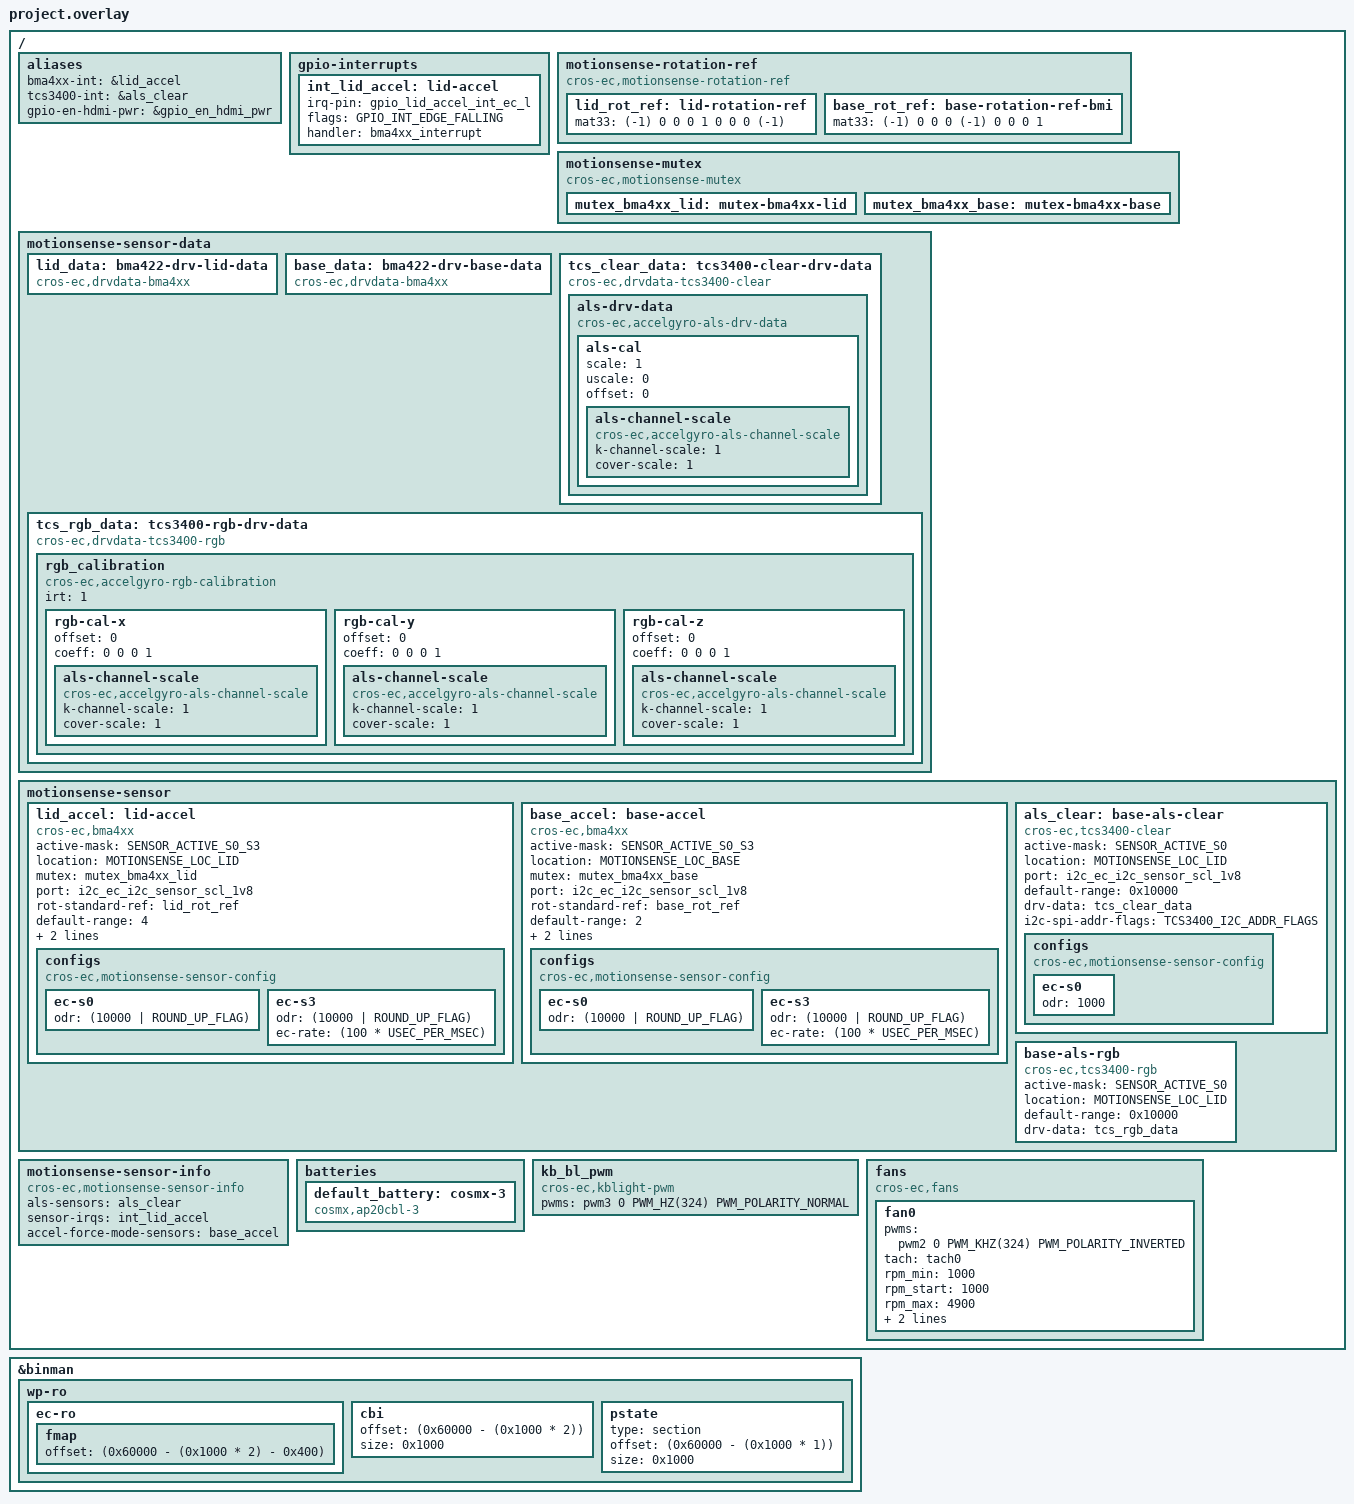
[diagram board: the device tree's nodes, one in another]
/* Copyright 2024 The ChromiumOS Authors
 * Use of this source code is governed by a BSD-style license that can be
 * found in the LICENSE file.
 */

#include <cros/cbi_flash.dtsi>
#include <dt-bindings/motionsense/utils.h>

#include "../arbitrage.dtsi"
#include "../common.dtsi"
#include "../usbc.dtsi"
#include "../usba.dtsi"
#include "../generated.dtsi"
#include "../interrupts.dtsi"
#include "../motionsense.dtsi"
#include "../keyboard.dtsi"
#include "../overlay.dtsi"
#include "../power_signal.dtsi"

/ {
	aliases {
		bma4xx-int = &lid_accel;
		tcs3400-int = &als_clear;
		gpio-en-hdmi-pwr = &gpio_en_hdmi_pwr;
	};
	gpio-interrupts {
		/delete-node/ ec-imu;
		int_lid_accel: lid-accel {
				irq-pin = <&gpio_lid_accel_int_ec_l>;
				flags = <GPIO_INT_EDGE_FALLING>;
				handler = "bma4xx_interrupt";
		};
	};

	/* Rotation matrix used by drivers. */
	motionsense-rotation-ref {
		compatible = "cros-ec,motionsense-rotation-ref";
		lid_rot_ref: lid-rotation-ref {
			mat33 = <(-1) 0 0
				 0 1 0
				 0 0 (-1)>;
		};

		base_rot_ref: base-rotation-ref-bmi {
			mat33 = <(-1) 0 0
				 0 (-1) 0
				 0 0 1>;
		};
	};

	/*
	 * Declare mutexes used by sensor drivers.
	 * A mutex node is used to create an instance of mutex_t.
	 * A mutex node is referenced by a sensor node if the
	 * corresponding sensor driver needs to use the
	 * instance of the mutex.
	 */

	motionsense-mutex {
		compatible = "cros-ec,motionsense-mutex";
		mutex_bma4xx_lid: mutex-bma4xx-lid {
		};
		mutex_bma4xx_base: mutex-bma4xx-base {
		};
	};

	/* Driver specific data */
	motionsense-sensor-data {
		lid_data: bma422-drv-lid-data {
			compatible = "cros-ec,drvdata-bma4xx";
			status = "okay";
		};
		base_data: bma422-drv-base-data {
			compatible = "cros-ec,drvdata-bma4xx";
			status = "okay";
		};
		tcs_clear_data: tcs3400-clear-drv-data {
			compatible = "cros-ec,drvdata-tcs3400-clear";
			status = "okay";

			als-drv-data {
				compatible = "cros-ec,accelgyro-als-drv-data";
				als-cal {
					scale = <1>;
					uscale = <0>;
					offset = <0>;
					als-channel-scale {
					compatible =
					"cros-ec,accelgyro-als-channel-scale";
						k-channel-scale = <1>;
						cover-scale = <1>;
					};
				};
			};
		};
		tcs_rgb_data: tcs3400-rgb-drv-data {
			compatible = "cros-ec,drvdata-tcs3400-rgb";
			status = "okay";

			/* node for rgb_calibration_t defined in accelgyro.h */
			rgb_calibration {
				compatible =
					"cros-ec,accelgyro-rgb-calibration";

				irt = <1>;

				rgb-cal-x {
					offset = <0>;
					coeff = <0 0 0 1>;
					als-channel-scale {
					compatible =
					"cros-ec,accelgyro-als-channel-scale";
						k-channel-scale = <1>;
						cover-scale = <1>;
					};
				};
				rgb-cal-y {
					offset = <0>;
					coeff = <0 0 0 1>;
					als-channel-scale {
					compatible =
					"cros-ec,accelgyro-als-channel-scale";
						k-channel-scale = <1>;
						cover-scale = <1>;
					};
				};
				rgb-cal-z {
					offset = <0>;
					coeff = <0 0 0 1>;
					als-channel-scale {
					compatible =
					"cros-ec,accelgyro-als-channel-scale";
						k-channel-scale = <1>;
						cover-scale = <1>;
					};
				};
			};
		};
	};

	/* List of motion sensors that create motion_sensors array. */
	motionsense-sensor {
		lid_accel: lid-accel {
			compatible = "cros-ec,bma4xx";
			status = "okay";

			active-mask = "SENSOR_ACTIVE_S0_S3";
			location = "MOTIONSENSE_LOC_LID";
			mutex = <&mutex_bma4xx_lid>;
			port = <&i2c_ec_i2c_sensor_scl_1v8>;
			rot-standard-ref = <&lid_rot_ref>;
			default-range = <4>; /* to meet CDD 7.3.1/C-1-4 reqs. */
			drv-data = <&lid_data>;
			i2c-spi-addr-flags = "BMA4_I2C_ADDR_PRIMARY";
			configs {
				compatible =
					"cros-ec,motionsense-sensor-config";
				ec-s0 {
					odr = <(10000 | ROUND_UP_FLAG)>;
				};
				ec-s3 {
					odr = <(10000 | ROUND_UP_FLAG)>;
					ec-rate = <(100 * USEC_PER_MSEC)>;
				};
			};
		};
		base_accel: base-accel {
			compatible = "cros-ec,bma4xx";
			status = "okay";

			active-mask = "SENSOR_ACTIVE_S0_S3";
			location = "MOTIONSENSE_LOC_BASE";
			mutex = <&mutex_bma4xx_base>;
			port = <&i2c_ec_i2c_sensor_scl_1v8>;
			rot-standard-ref = <&base_rot_ref>;
			default-range = <2>;
			drv-data = <&base_data>;
			i2c-spi-addr-flags = "BMA4_I2C_ADDR_SECONDARY";
			configs {
				compatible =
					"cros-ec,motionsense-sensor-config";
				ec-s0 {
					odr = <(10000 | ROUND_UP_FLAG)>;
				};
				ec-s3 {
					odr = <(10000 | ROUND_UP_FLAG)>;
					ec-rate = <(100 * USEC_PER_MSEC)>;
				};
			};
		};
		als_clear: base-als-clear {
			compatible = "cros-ec,tcs3400-clear";
			status = "okay";

			active-mask = "SENSOR_ACTIVE_S0";
			location = "MOTIONSENSE_LOC_LID";
			port = <&i2c_ec_i2c_sensor_scl_1v8>;
			default-range = <0x10000>;
			drv-data = <&tcs_clear_data>;
			i2c-spi-addr-flags = "TCS3400_I2C_ADDR_FLAGS";
			configs {
				compatible =
					"cros-ec,motionsense-sensor-config";
				ec-s0 {
					/* Run ALS sensor in S0 */
					odr = <1000>;
				};
			};
		};

		base-als-rgb {
			compatible = "cros-ec,tcs3400-rgb";
			status = "okay";

			active-mask = "SENSOR_ACTIVE_S0";
			location = "MOTIONSENSE_LOC_LID";
			default-range = <0x10000>; /* scale = 1x, uscale = 0 */
			drv-data = <&tcs_rgb_data>;
		};
	};

	/* High level description info */
	motionsense-sensor-info {
		compatible = "cros-ec,motionsense-sensor-info";

		/* list of entries for motion_als_sensors */
		als-sensors = <&als_clear>;

		/*
		 * List of GPIO interrupts that have to be enabled at initial
		 * stage.
		 */
		sensor-irqs = <&int_lid_accel>;

		/* List of sensors in force mode */
		accel-force-mode-sensors = <&base_accel>;
	};

	batteries {
		default_battery: cosmx-3 {
			compatible = "cosmx,ap20cbl-3", "battery-smart";
		};
	};

	kb_bl_pwm {
		compatible = "cros-ec,kblight-pwm";
		pwms = <&pwm3 0 PWM_HZ(324) PWM_POLARITY_NORMAL>;
		status = "okay";
	};

	fans {
		compatible = "cros-ec,fans";

		fan0: fan0 {
			pwms = <&pwm2 0 PWM_KHZ(324) PWM_POLARITY_INVERTED>;
			tach = <&tach0>;
			rpm_min = <1000>;
			rpm_start = <1000>;
			rpm_max = <4900>;
			enable_gpio = <&gpio_en_pp5000_fan>;
			use_fast_start;
		};
	};
};

/*
 * When CBI in flash is enabled, setup RO flash layout as follows:
 *   RO binary:    0x00000:0x5DFFF
 *   FMAP:         0x5DC00:0x5DFFF
 *   CBI flash:    0x5E000:0x5EFFF
 *   PSTATE block: 0x5F000:0x5FFFF
 */
&binman {
	wp-ro {
		/*
		 * Delete the pstate node so that we can force it to be the
		 * last sub-section. binman doesn't handle sub-sections with
		 * out of order offsets.
		 */
		 /delete-node/ pstate;

		 ec-ro {
			fmap {
				offset =  <(0x60000 - (0x1000 * 2) - 0x400)>;
				/*
				* don't specify 'size = <0x400>' here so
				* it is auto-assigned to the fmap size.
				*/
			};
		};
		cbi {
			offset = <(0x60000 - (0x1000 * 2))>;
			size = <0x1000>;
		};
		pstate {
			type = "section";
			offset = <(0x60000 - (0x1000 * 1))>;
			size = <0x1000>;
		};
	};
};
